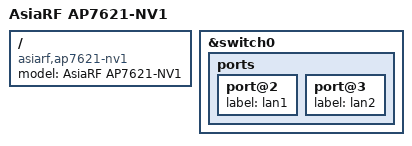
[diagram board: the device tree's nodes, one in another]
// SPDX-License-Identifier: GPL-2.0-or-later OR MIT

#include "mt7621_asiarf_ap7621.dtsi"

/ {
	compatible = "asiarf,ap7621-nv1", "mediatek,mt7621-soc";
	model = "AsiaRF AP7621-NV1";
};

&switch0 {
	ports {
		port@2 {
			status = "okay";
			label = "lan1";
		};

		port@3 {
			status = "okay";
			label = "lan2";
		};
	};
};
